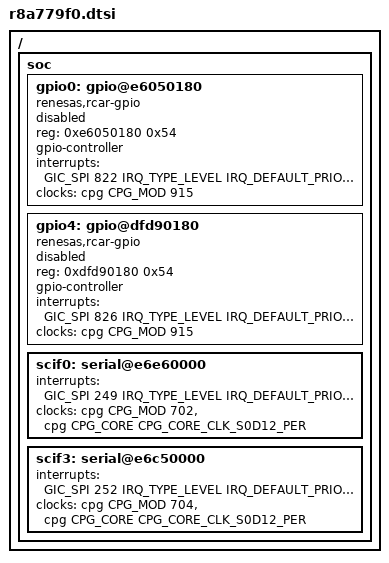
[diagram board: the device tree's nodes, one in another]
/*
 * Copyright (c) 2022 IoT.bzh
 *
 * SPDX-License-Identifier: Apache-2.0
 */

#include <renesas/gen4/rcar_gen4_cr52.dtsi>
#include <zephyr/dt-bindings/gpio/gpio.h>

/ {
    soc {
        gpio0: gpio@e6050180 {
            compatible = "renesas,rcar-gpio";
            reg = <0xe6050180 0x54>;
            #gpio-cells = <2>;
            gpio-controller;
            interrupts = <GIC_SPI 822 IRQ_TYPE_LEVEL IRQ_DEFAULT_PRIORITY>;
            clocks = <&cpg CPG_MOD 915>;
            status = "disabled";
        };

        /* Cant manage to use GPIOs from PFSS domain buses yet */
        gpio4: gpio@dfd90180 {
            compatible = "renesas,rcar-gpio";
            reg = <0xdfd90180 0x54>;
            #gpio-cells = <2>;
            gpio-controller;
            interrupts = <GIC_SPI 826 IRQ_TYPE_LEVEL IRQ_DEFAULT_PRIORITY>;
            clocks = <&cpg CPG_MOD 915>;
            status = "disabled";
        };

        scif0: serial@e6e60000 {
            interrupts = <GIC_SPI 249 IRQ_TYPE_LEVEL IRQ_DEFAULT_PRIORITY>;
            clocks = <&cpg CPG_MOD 702>, <&cpg CPG_CORE CPG_CORE_CLK_S0D12_PER>;
        };

        scif3: serial@e6c50000 {
            interrupts = <GIC_SPI 252 IRQ_TYPE_LEVEL IRQ_DEFAULT_PRIORITY>;
            clocks = <&cpg CPG_MOD 704>, <&cpg CPG_CORE CPG_CORE_CLK_S0D12_PER>;
        };
    };
};
